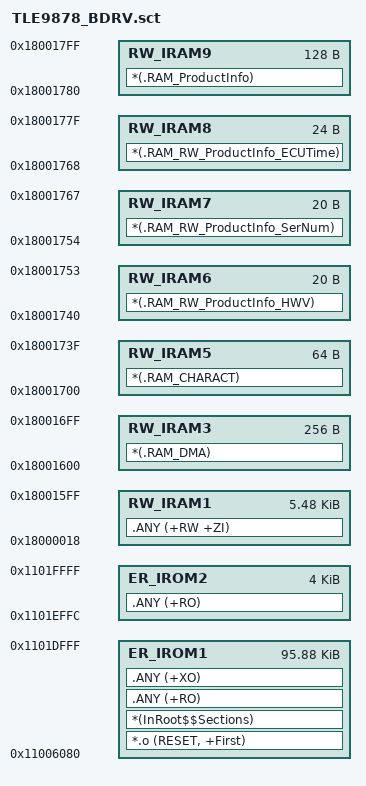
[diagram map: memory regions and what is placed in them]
; *************************************************************
; *** Scatter-Loading Description File generated by uVision ***
; *************************************************************


;LR_IROM1 0x11000000 0x0001EFFC  {    ; load region size_region
;  ER_IROM1 0x11000000 0x0001EFFC  {  ; load address = execution address
;  LR_IROM1 0x11000000 0x00017F80    {    ; load region size_region
;  ER_IROM1 0x11000000 0x00017F80  {  ; load address = execution address

  LR_IROM1 0x11006080 0x00017F80    {    ; load region size_region
  ER_IROM1 0x11006080 0x00017F80  {  ; load address = execution address
   *.o (RESET, +First)
   *(InRoot$$Sections)
   .ANY (+RO)
   .ANY (+XO)
  }


;; Note: Don't change the order of RAM(1), Heap(2) and Stack(3)-Area
  ;; Define space of User-RAM, RW data
   RW_IRAM1 0x18000018  0x15E8 ;0xc00-0x18~3k
   {  
    .ANY (+RW +ZI)
   }
;   RW_IRAM2 0x18001300  0x200 ;0.5k
;   {  
;	*(.RAM_GLOBAL)
;   }
   RW_IRAM3 0x18001600  0x100 ;0.25K
   {  
	*(.RAM_DMA)
   } 
   RW_IRAM5 0x18001700  0x40  ;64 byte
   {  
	*(.RAM_CHARACT)
   }

   RW_IRAM6 0x18001740  0x14  ;20 byte
   {  
      *(.RAM_RW_ProductInfo_HWV)
   }
   RW_IRAM7 0x18001754  0x14  ;20 byte
   {  
      *(.RAM_RW_ProductInfo_SerNum)
   }
   RW_IRAM8 0x18001768  0x18  ;24 byte
   {  
      *(.RAM_RW_ProductInfo_ECUTime)
   }

   RW_IRAM9 0x18001780  0x80  ;0.125K 128byte
   {  
	*(.RAM_ProductInfo)
   }


} ;; ----- End of LR_IROM1 -----




LR_IROM2 0x1101EFFC 0x00001004  {
  ER_IROM2 0x1101EFFC 0x00001004  {  ; load address = execution address
   .ANY (+RO)
  }
}







